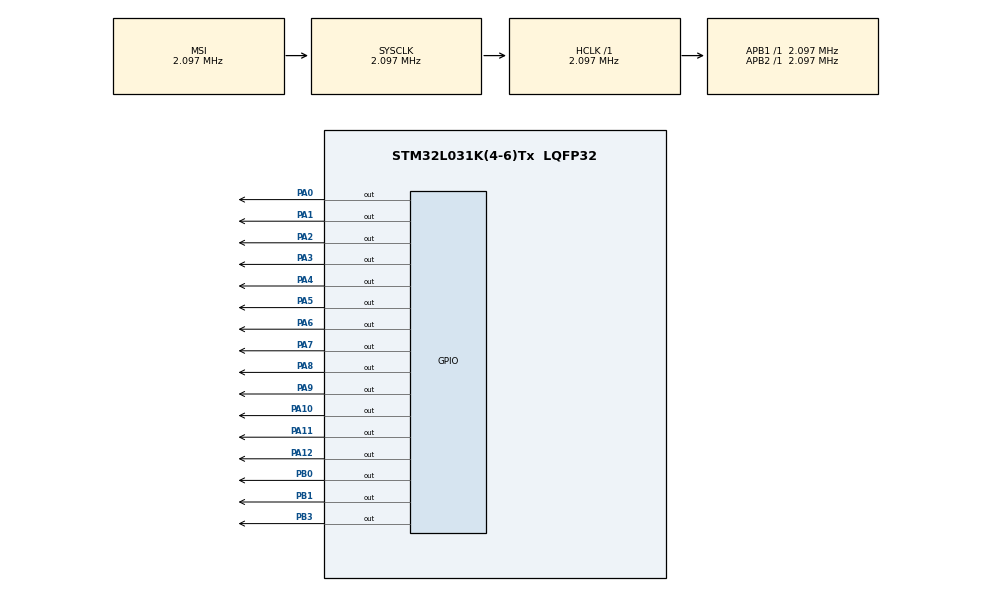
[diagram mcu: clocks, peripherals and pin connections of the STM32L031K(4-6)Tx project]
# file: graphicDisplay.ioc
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Mcu.Family=STM32L0
RCC.MSI_VALUE=2097000
ProjectManager.StackSize=0x400
RCC.HSI16_VALUE=16000000
PA12.Signal=GPIO_Output
ProjectManager.TargetToolchain=STM32CubeIDE
RCC.APB2TimFreq_Value=2097000
PA9.Signal=GPIO_Output
RCC.LSE_VALUE=32768
PA1.Signal=GPIO_Output
RCC.AHBFreq_Value=2097000
PA5.Signal=GPIO_Output
RCC.HSE_VALUE=8000000
board=custom
RCC.VCOOutputFreq_Value=48000000
PA0-CK_IN.Signal=GPIO_Output
RCC.APB2Freq_Value=2097000
PA8.Signal=GPIO_Output
Mcu.Name=STM32L031K(4-6)Tx
PA2.Signal=GPIO_Output
PB3.Signal=GPIO_Output
PA4.Signal=GPIO_Output
RCC.SYSCLKFreq_VALUE=2097000
Mcu.Package=LQFP32
PB1.Signal=GPIO_Output
PA6.Signal=GPIO_Output
PA11.Signal=GPIO_Output
PA10.Signal=GPIO_Output
ProjectManager.HeapSize=0x200
RCC.HSI_VALUE=16000000
RCC.APB1TimFreq_Value=2097000
RCC.APB1Freq_Value=2097000
PB0.Signal=GPIO_Output
PA3.Signal=GPIO_Output
PA7.Signal=GPIO_Output

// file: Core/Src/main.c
/* USER CODE BEGIN Header */
/**
  ******************************************************************************
  * @file           : main.c
  * @brief          : Main program body
  ******************************************************************************
  * @attention
  *
  * <h2><center>&copy; Copyright (c) 2024 STMicroelectronics.
  * All rights reserved.</center></h2>
  *
  * This software component is licensed by ST under BSD 3-Clause license,
  * the "License"; You may not use this file except in compliance with the
  * License. You may obtain a copy of the License at:
  *                        opensource.org/licenses/BSD-3-Clause
  *
  ******************************************************************************
  */
/* USER CODE END Header */
#include "main.h"
#include "lcd.h"

void SystemClock_Config(void);
static void MX_GPIO_Init(void);
void delay_us(uint32_t us);

int main(void)
{
  /* USER CODE BEGIN 1 */
	//uint8_t var1, var2=0;
	//uint8_t cPage, cC1mn;
  /* USER CODE END 1 */

  /* MCU Configuration--------------------------------------------------------*/

  /* Reset of all peripherals, Initializes the Flash interface and the Systick. */
  HAL_Init();

  /* Configure the system clock */
  SystemClock_Config();

  /* Initialize all configured peripherals */
  MX_GPIO_Init();
  HAL_Delay(100);
  GLCD_Initalize();
  HAL_Delay(100);
  GLCD_ClearScreen();

  /* USER CODE BEGIN 2 */
 // LCDInit();
  /* USER CODE END 2 */

  /* Infinite loop */
  while (1)
  {
	 // HAL_GPIO_TogglePin(GPIOB, GPIO_PIN_3);
	 // delay_us(500);
	  GLCD_GoTo(0,0);
	  GLCD_WriteString("Hello World");
	  HAL_GPIO_TogglePin(GPIOB, GPIO_PIN_3);
	  HAL_Delay(1000);
  }
}

void SystemClock_Config(void)
{
  RCC_OscInitTypeDef RCC_OscInitStruct = {0};
  RCC_ClkInitTypeDef RCC_ClkInitStruct = {0};

  /** Configure the main internal regulator output voltage
  */
  __HAL_PWR_VOLTAGESCALING_CONFIG(PWR_REGULATOR_VOLTAGE_SCALE1);
  /** Initializes the RCC Oscillators according to the specified parameters
  * in the RCC_OscInitTypeDef structure.
  */
  RCC_OscInitStruct.OscillatorType = RCC_OSCILLATORTYPE_MSI;
  RCC_OscInitStruct.MSIState = RCC_MSI_ON;
  RCC_OscInitStruct.MSICalibrationValue = 0;
  RCC_OscInitStruct.MSIClockRange = RCC_MSIRANGE_5;
  RCC_OscInitStruct.PLL.PLLState = RCC_PLL_NONE;
  if (HAL_RCC_OscConfig(&RCC_OscInitStruct) != HAL_OK)
  {
    Error_Handler();
  }
  /** Initializes the CPU, AHB and APB buses clocks
  */
  RCC_ClkInitStruct.ClockType = RCC_CLOCKTYPE_HCLK|RCC_CLOCKTYPE_SYSCLK
                              |RCC_CLOCKTYPE_PCLK1|RCC_CLOCKTYPE_PCLK2;
  RCC_ClkInitStruct.SYSCLKSource = RCC_SYSCLKSOURCE_MSI;
  RCC_ClkInitStruct.AHBCLKDivider = RCC_SYSCLK_DIV1;
  RCC_ClkInitStruct.APB1CLKDivider = RCC_HCLK_DIV1;
  RCC_ClkInitStruct.APB2CLKDivider = RCC_HCLK_DIV1;

  if (HAL_RCC_ClockConfig(&RCC_ClkInitStruct, FLASH_LATENCY_0) != HAL_OK)
  {
    Error_Handler();
  }
}

static void MX_GPIO_Init(void)
{
  GPIO_InitTypeDef GPIO_InitStruct = {0};

  /* GPIO Ports Clock Enable */
  __HAL_RCC_GPIOA_CLK_ENABLE();
  __HAL_RCC_GPIOB_CLK_ENABLE();

  /*Configure GPIO pin Output Level */
  HAL_GPIO_WritePin(GPIOA, GPIO_PIN_0|GPIO_PIN_1|GPIO_PIN_2|GPIO_PIN_3
                          |GPIO_PIN_4|GPIO_PIN_5|GPIO_PIN_6|GPIO_PIN_7
                          |GPIO_PIN_8|GPIO_PIN_9|GPIO_PIN_10|GPIO_PIN_11
                          |GPIO_PIN_12, GPIO_PIN_RESET);

  /*Configure GPIO pin Output Level */
  HAL_GPIO_WritePin(GPIOB, GPIO_PIN_0|GPIO_PIN_1|GPIO_PIN_3, GPIO_PIN_RESET);

  /*Configure GPIO pins : PA0 PA1 PA2 PA3
                           PA4 PA5 PA6 PA7
                           PA8 PA9 PA10 PA11
                           PA12 */
  GPIO_InitStruct.Pin = GPIO_PIN_0|GPIO_PIN_1|GPIO_PIN_2|GPIO_PIN_3
                          |GPIO_PIN_4|GPIO_PIN_5|GPIO_PIN_6|GPIO_PIN_7
                          |GPIO_PIN_8|GPIO_PIN_9|GPIO_PIN_10|GPIO_PIN_11
                          |GPIO_PIN_12;
  GPIO_InitStruct.Mode = GPIO_MODE_OUTPUT_PP;
  GPIO_InitStruct.Pull = GPIO_NOPULL;
  GPIO_InitStruct.Speed = GPIO_SPEED_FREQ_LOW;
  HAL_GPIO_Init(GPIOA, &GPIO_InitStruct);

  /*Configure GPIO pins : PB0 PB1 PB3 */
  GPIO_InitStruct.Pin = GPIO_PIN_0|GPIO_PIN_1|GPIO_PIN_3;
  GPIO_InitStruct.Mode = GPIO_MODE_OUTPUT_PP;
  GPIO_InitStruct.Pull = GPIO_NOPULL;
  GPIO_InitStruct.Speed = GPIO_SPEED_FREQ_LOW;
  HAL_GPIO_Init(GPIOB, &GPIO_InitStruct);

  HAL_GPIO_WritePin(KS0108_DATA_PORT, GPIO_PIN_0 | GPIO_PIN_1 | GPIO_PIN_2 | GPIO_PIN_3 | GPIO_PIN_4 | GPIO_PIN_5 | GPIO_PIN_6 | GPIO_PIN_7, GPIO_PIN_RESET);
}

void Error_Handler(void)
{
  __disable_irq();
  while (1)
  {
  }
}

/************************ (C) COPYRIGHT STMicroelectronics *****END OF FILE****/
